VERSION "created by canmatrix"

NS_ :

BS_:

BU_: User ADM_PC_LL25 ADM_PC_BC25 ADM_PC_BP25 ADM_PC_BI25

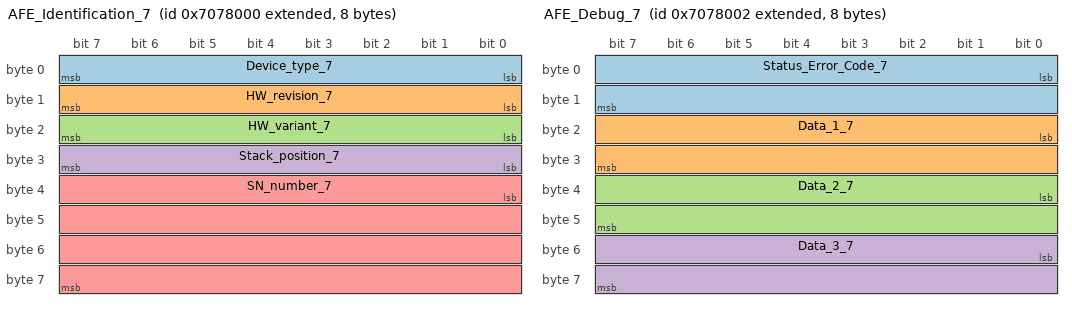
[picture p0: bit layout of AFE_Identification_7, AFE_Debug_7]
BO_ 2265415680 AFE_Identification_7: 8 ADM_PC_BP25
 SG_ Device_type_7 : 0|8@1+ (1,0) [0|255] "" Vector__XXX
 SG_ HW_revision_7 : 8|8@1+ (1,0) [0|255] "" Vector__XXX
 SG_ HW_variant_7 : 16|8@1+ (1,0) [0|255] "" Vector__XXX
 SG_ Stack_position_7 : 24|8@1+ (1,0) [0|255] "" Vector__XXX
 SG_ SN_number_7 : 32|32@1+ (1,0) [0|4294967295] "" Vector__XXX

BO_ 2265415681 AFE_FwInfo_7: 8 ADM_PC_BP25
 SG_ FW_info_mux_7 M : 56|8@1+ (1,0) [0|255] "" Vector__XXX
 SG_ FW_revision_0_7 m0 : 0|8@1+ (1,0) [0|255] "" Vector__XXX
 SG_ FW_revision_1_7 m0 : 8|8@1+ (1,0) [0|255] "" Vector__XXX
 SG_ FW_revision_2_7 m0 : 16|8@1+ (1,0) [0|255] "" Vector__XXX
 SG_ FW_revision_3_7 m0 : 24|8@1+ (1,0) [0|255] "" Vector__XXX
 SG_ FW_revision_4_7 m0 : 32|8@1+ (1,0) [0|255] "" Vector__XXX
 SG_ FW_revision_5_7 m0 : 40|8@1+ (1,0) [0|255] "" Vector__XXX
 SG_ FW_revision_6_7 m0 : 48|8@1+ (1,0) [0|255] "" Vector__XXX
 SG_ FW_revision_7_7 m1 : 0|8@1+ (1,0) [0|255] "" Vector__XXX
 SG_ FW_revision_8_7 m1 : 8|8@1+ (1,0) [0|255] "" Vector__XXX
 SG_ FW_revision_9_7 m1 : 16|8@1+ (1,0) [0|255] "" Vector__XXX
 SG_ FW_revision_10_7 m1 : 24|8@1+ (1,0) [0|255] "" Vector__XXX
 SG_ FW_revision_11_7 m1 : 32|8@1+ (1,0) [0|255] "" Vector__XXX
 SG_ FW_revision_12_7 m1 : 40|8@1+ (1,0) [0|255] "" Vector__XXX
 SG_ FW_revision_13_7 m1 : 48|8@1+ (1,0) [0|255] "" Vector__XXX
 SG_ FW_datecode_0_7 m2 : 0|8@1+ (1,0) [0|255] "" Vector__XXX
 SG_ FW_datecode_1_7 m2 : 8|8@1+ (1,0) [0|255] "" Vector__XXX
 SG_ FW_datecode_2_7 m2 : 16|8@1+ (1,0) [0|255] "" Vector__XXX
 SG_ FW_datecode_3_7 m2 : 24|8@1+ (1,0) [0|255] "" Vector__XXX
 SG_ FW_datecode_4_7 m2 : 32|8@1+ (1,0) [0|255] "" Vector__XXX
 SG_ FW_datecode_5_7 m2 : 40|8@1+ (1,0) [0|255] "" Vector__XXX
 SG_ FW_datecode_6_7 m2 : 48|8@1+ (1,0) [0|255] "" Vector__XXX
 SG_ FW_datecode_7_7 m3 : 0|8@1+ (1,0) [0|255] "" Vector__XXX
 SG_ FW_datecode_8_7 m3 : 8|8@1+ (1,0) [0|255] "" Vector__XXX
 SG_ FW_datecode_9_7 m3 : 16|8@1+ (1,0) [0|255] "" Vector__XXX
 SG_ FW_datecode_10_7 m3 : 24|8@1+ (1,0) [0|255] "" Vector__XXX
 SG_ FW_datecode_11_7 m3 : 32|8@1+ (1,0) [0|255] "" Vector__XXX
 SG_ FW_datecode_12_7 m3 : 40|8@1+ (1,0) [0|255] "" Vector__XXX
 SG_ FW_datecode_13_7 m3 : 48|8@1+ (1,0) [0|255] "" Vector__XXX

BO_ 2265415693 _AFE_Boot_FwInfo_7: 8 ADM_PC_BP25
 SG_ Boot_FW_info_mux_7 M : 56|8@1+ (1,0) [0|255] "" Vector__XXX
 SG_ FW_revision_0_7 m0 : 0|8@1+ (1,0) [0|255] "" Vector__XXX
 SG_ FW_revision_1_7 m0 : 8|8@1+ (1,0) [0|255] "" Vector__XXX
 SG_ FW_revision_2_7 m0 : 16|8@1+ (1,0) [0|255] "" Vector__XXX
 SG_ FW_revision_3_7 m0 : 24|8@1+ (1,0) [0|255] "" Vector__XXX
 SG_ FW_revision_4_7 m0 : 32|8@1+ (1,0) [0|255] "" Vector__XXX
 SG_ FW_revision_5_7 m0 : 40|8@1+ (1,0) [0|255] "" Vector__XXX
 SG_ FW_revision_6_7 m0 : 48|8@1+ (1,0) [0|255] "" Vector__XXX
 SG_ FW_revision_7_7 m1 : 0|8@1+ (1,0) [0|255] "" Vector__XXX
 SG_ FW_revision_8_7 m1 : 8|8@1+ (1,0) [0|255] "" Vector__XXX
 SG_ FW_revision_9_7 m1 : 16|8@1+ (1,0) [0|255] "" Vector__XXX
 SG_ FW_revision_10_7 m1 : 24|8@1+ (1,0) [0|255] "" Vector__XXX
 SG_ FW_revision_11_7 m1 : 32|8@1+ (1,0) [0|255] "" Vector__XXX
 SG_ FW_revision_12_7 m1 : 40|8@1+ (1,0) [0|255] "" Vector__XXX
 SG_ FW_revision_13_7 m1 : 48|8@1+ (1,0) [0|255] "" Vector__XXX
 SG_ FW_datecode_0_7 m2 : 0|8@1+ (1,0) [0|255] "" Vector__XXX
 SG_ FW_datecode_1_7 m2 : 8|8@1+ (1,0) [0|255] "" Vector__XXX
 SG_ FW_datecode_2_7 m2 : 16|8@1+ (1,0) [0|255] "" Vector__XXX
 SG_ FW_datecode_3_7 m2 : 24|8@1+ (1,0) [0|255] "" Vector__XXX
 SG_ FW_datecode_4_7 m2 : 32|8@1+ (1,0) [0|255] "" Vector__XXX
 SG_ FW_datecode_5_7 m2 : 40|8@1+ (1,0) [0|255] "" Vector__XXX
 SG_ FW_datecode_6_7 m2 : 48|8@1+ (1,0) [0|255] "" Vector__XXX
 SG_ FW_datecode_7_7 m3 : 0|8@1+ (1,0) [0|255] "" Vector__XXX
 SG_ FW_datecode_8_7 m3 : 8|8@1+ (1,0) [0|255] "" Vector__XXX
 SG_ FW_datecode_9_7 m3 : 16|8@1+ (1,0) [0|255] "" Vector__XXX
 SG_ FW_datecode_10_7 m3 : 24|8@1+ (1,0) [0|255] "" Vector__XXX
 SG_ FW_datecode_11_7 m3 : 32|8@1+ (1,0) [0|255] "" Vector__XXX
 SG_ FW_datecode_12_7 m3 : 40|8@1+ (1,0) [0|255] "" Vector__XXX
 SG_ FW_datecode_13_7 m3 : 48|8@1+ (1,0) [0|255] "" Vector__XXX

BO_ 2265415682 AFE_Debug_7: 8 ADM_PC_BP25
 SG_ Status_Error_Code_7 : 0|16@1+ (1,0) [0|65535] "" Vector__XXX
 SG_ Data_1_7 : 16|16@1+ (1,0) [0|65535] "" Vector__XXX
 SG_ Data_2_7 : 32|16@1+ (1,0) [0|65535] "" Vector__XXX
 SG_ Data_3_7 : 48|16@1+ (1,0) [0|65535] "" Vector__XXX

BO_ 2265415687 AFE_Status_7: 8 ADM_PC_BP25
 SG_ Running_7 : 0|1@1+ (1,0) [0|1] "" Vector__XXX
 SG_ PWM_7 : 1|1@1+ (1,0) [0|1] "" Vector__XXX
 SG_ Current_dc_loop_mode_7 : 2|1@1+ (1,0) [0|1] "" Vector__XXX
 SG_ Current_ac_loop_mode_7 : 3|1@1+ (1,0) [0|1] "" Vector__XXX
 SG_ Buck_7 : 5|1@1+ (1,0) [0|1] "" Vector__XXX
 SG_ Boost_7 : 6|1@1+ (1,0) [0|1] "" Vector__XXX
 SG_ Precharge_dc_buck_mode_7 : 7|1@1+ (1,0) [0|1] "" Vector__XXX
 SG_ Precharge_dc_boost_mode_7 : 8|1@1+ (1,0) [0|1] "" Vector__XXX
 SG_ Rectifier_3ph_7 : 9|1@1+ (1,0) [0|1] "" Vector__XXX
 SG_ Stack_mode_7 : 10|1@1+ (1,0) [0|1] "" Vector__XXX
 SG_ Master_7 : 11|1@1+ (1,0) [0|1] "" Vector__XXX
 SG_ Slave_7 : 12|1@1+ (1,0) [0|1] "" Vector__XXX
 SG_ Inverter_1ph_7 : 13|1@1+ (1,0) [0|1] "" Vector__XXX
 SG_ Boost_Neutral_7 : 14|1@1+ (1,0) [0|1] "" Vector__XXX
 SG_ Rectifier_1ph_7 : 15|1@1+ (1,0) [0|1] "" Vector__XXX
 SG_ Inverter_3ph_7 : 16|1@1+ (1,0) [0|1] "" Vector__XXX
 SG_ Ready_7 : 17|1@1+ (1,0) [0|1] "" Vector__XXX
 SG_ Inverter_1ph_Sync_7 : 18|1@1+ (1,0) [0|1] "" Vector__XXX
 SG_ Neutral_7 : 19|1@1+ (1,0) [0|1] "" Vector__XXX
 SG_ Rectifier_1ph_Buck_7 : 20|1@1+ (1,0) [0|1] "" Vector__XXX
 SG_ Inverter_1ph_Boost_7 : 21|1@1+ (1,0) [0|1] "" Vector__XXX
 SG_ Rectifier_distributed_7 : 22|1@1+ (1,0) [0|1] "" Vector__XXX
 SG_ MPPT_buck_7 : 23|1@1+ (1,0) [0|1] "" Vector__XXX
 SG_ MPPT_boost_7 : 24|1@1+ (1,0) [0|1] "" Vector__XXX
 SG_ Buck_2p_float_7 : 25|1@1+ (1,0) [0|1] "" Vector__XXX
 SG_ Inverter_1ph_Distributed_7 : 26|1@1+ (1,0) [0|1] "" Vector__XXX

BO_ 2265415686 AFE_Faults_7: 3 ADM_PC_BP25
 SG_ Protection_trip_internal_7 : 0|1@1+ (1,0) [0|1] "" Vector__XXX
 SG_ Protection_trip_external_7 : 1|1@1+ (1,0) [0|1] "" Vector__XXX
 SG_ Phase_U_overcurrent_7 : 2|1@1+ (1,0) [0|1] "" Vector__XXX
 SG_ Phase_U_overvoltage_7 : 3|1@1+ (1,0) [0|1] "" Vector__XXX
 SG_ Phase_U_undervoltage_7 : 4|1@1+ (1,0) [0|1] "" Vector__XXX
 SG_ Phase_V_overvoltage_7 : 5|1@1+ (1,0) [0|1] "" Vector__XXX
 SG_ Phase_V_undervoltage_7 : 6|1@1+ (1,0) [0|1] "" Vector__XXX
 SG_ Phase_V_overcurrent_7 : 7|1@1+ (1,0) [0|1] "" Vector__XXX
 SG_ Phase_W_overvoltage_7 : 8|1@1+ (1,0) [0|1] "" Vector__XXX
 SG_ Phase_W_undervoltage_7 : 9|1@1+ (1,0) [0|1] "" Vector__XXX
 SG_ Phase_W_overcurrent_7 : 10|1@1+ (1,0) [0|1] "" Vector__XXX
 SG_ DC_undervoltage_7 : 11|1@1+ (1,0) [0|1] "" Vector__XXX
 SG_ DC_overvoltage_7 : 12|1@1+ (1,0) [0|1] "" Vector__XXX
 SG_ MOSFET_overtemperature_7 : 13|1@1+ (1,0) [0|1] "" Vector__XXX
 SG_ Inductor_overtemperature_7 : 14|1@1+ (1,0) [0|1] "" Vector__XXX
 SG_ Keep_Alive_not_served_7 : 15|1@1+ (1,0) [0|1] "" Vector__XXX
 SG_ PLL_not_locked_7 : 16|1@1+ (1,0) [0|1] "" Vector__XXX
 SG_ NFO_7 : 20|1@1+ (1,0) [0|1] "" Vector__XXX
 SG_ Measurement_system_failure_7 : 21|1@1+ (1,0) [0|1] "" Vector__XXX
 SG_ EEPROM_failure_7 : 22|1@1+ (1,0) [0|1] "" Vector__XXX
 SG_ System_7 : 23|1@1+ (1,0) [0|1] "" Vector__XXX

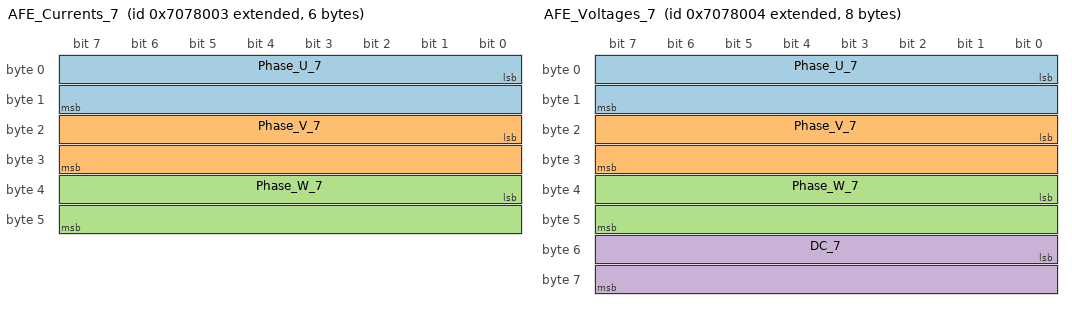
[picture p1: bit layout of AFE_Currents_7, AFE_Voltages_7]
BO_ 2265415683 AFE_Currents_7: 6 ADM_PC_BP25
 SG_ Phase_U_7 : 0|16@1- (0.01,0) [-327.68|327.67] "A" Vector__XXX
 SG_ Phase_V_7 : 16|16@1- (0.01,0) [-327.68|327.67] "A" Vector__XXX
 SG_ Phase_W_7 : 32|16@1- (0.01,0) [-327.68|327.67] "A" Vector__XXX

BO_ 2265415696 AFE_DC_Bus_current_7: 2 ADM_PC_BP25
 SG_ Bus_current_7 : 0|16@1- (0.01,0) [-327.68|327.67] "A" Vector__XXX

BO_ 2265415694 _AFE_Broadcast_7: 8 ADM_PC_BP25
 SG_ Diagnostics_Index_7 M : 56|8@1+ (1,0) [0|255] "" Vector__XXX
 SG_ Phase_U_7 m1 : 8|16@1- (0.01,0) [-327.68|327.67] "A" ADM_PC_BP25
 SG_ Phase_V_7 m1 : 24|16@1- (0.01,0) [-327.68|327.67] "A" ADM_PC_BP25
 SG_ Phase_W_7 m1 : 40|16@1- (0.01,0) [-327.68|327.67] "A" ADM_PC_BP25
 SG_ Stack_position_7 : 0|5@1+ (1,0) [0|31] "" ADM_PC_BP25
 SG_ Group_ID_7 : 5|3@1+ (1,0) [0|7] "" ADM_PC_BP25

BO_ 2265415684 AFE_Voltages_7: 8 ADM_PC_BP25
 SG_ Phase_U_7 : 0|16@1- (0.1,0) [-3276.8|3276.7] "V" Vector__XXX
 SG_ Phase_V_7 : 16|16@1- (0.1,0) [-3276.8|3276.7] "V" Vector__XXX
 SG_ Phase_W_7 : 32|16@1- (0.1,0) [-3276.8|3276.7] "V" Vector__XXX
 SG_ DC_7 : 48|16@1- (0.1,0) [-3276.8|3276.7] "V" Vector__XXX

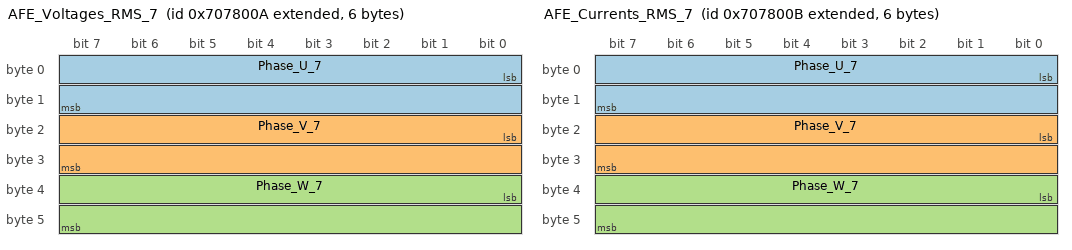
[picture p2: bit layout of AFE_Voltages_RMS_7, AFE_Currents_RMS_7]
BO_ 2265415690 AFE_Voltages_RMS_7: 6 ADM_PC_BP25
 SG_ Phase_U_7 : 0|16@1+ (0.1,0) [0|6553.5] "V" Vector__XXX
 SG_ Phase_V_7 : 16|16@1+ (0.1,0) [0|6553.5] "V" Vector__XXX
 SG_ Phase_W_7 : 32|16@1+ (0.1,0) [0|6553.5] "V" Vector__XXX

BO_ 2265415691 AFE_Currents_RMS_7: 6 ADM_PC_BP25
 SG_ Phase_U_7 : 0|16@1+ (0.01,0) [0.00|655.35] "A" Vector__XXX
 SG_ Phase_V_7 : 16|16@1+ (0.01,0) [0.00|655.35] "A" Vector__XXX
 SG_ Phase_W_7 : 32|16@1+ (0.01,0) [0.00|655.35] "A" Vector__XXX

BO_ 2265415692 AFE_Mains_7: 4 ADM_PC_BP25
 SG_ Frequency_7 : 0|16@1+ (0.01,0) [0.00|655.35] "Hz" Vector__XXX
 SG_ Phase_7 : 16|16@1- (0.1,0) [-3276.8|3276.7] "Deg." Vector__XXX

BO_ 2265415685 AFE_Temperatures_7: 4 ADM_PC_BP25
 SG_ Temp_Bridge_7 : 0|16@1- (0.01,0) [-327.68|327.67] "°C" Vector__XXX
 SG_ Temp_Inductors_7 : 16|16@1- (0.01,0) [-327.68|327.67] "°C" Vector__XXX

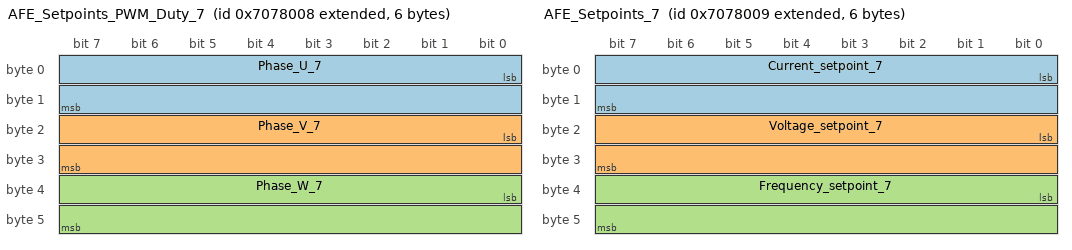
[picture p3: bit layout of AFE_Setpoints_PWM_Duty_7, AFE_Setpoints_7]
BO_ 2265415688 AFE_Setpoints_PWM_Duty_7: 6 ADM_PC_BP25
 SG_ Phase_U_7 : 0|16@1+ (0.001525902,0) [0E-009|99.999987570] "%" Vector__XXX
 SG_ Phase_V_7 : 16|16@1+ (0.001525902,0) [0E-009|99.999987570] "%" Vector__XXX
 SG_ Phase_W_7 : 32|16@1+ (0.001525902,0) [0E-009|99.999987570] "%" Vector__XXX

BO_ 2265415689 AFE_Setpoints_7: 6 ADM_PC_BP25
 SG_ Current_setpoint_7 : 0|16@1- (0.01,0) [-327.68|327.67] "A" Vector__XXX
 SG_ Voltage_setpoint_7 : 16|16@1+ (0.1,0) [0|6553.5] "V" Vector__XXX
 SG_ Frequency_setpoint_7 : 32|16@1+ (0.01,0) [0.00|655.35] "Hz" Vector__XXX

BO_ 2265383008 AFE_Keep_Alive_7: 1 User
 SG_ Keep_Alive_Enable_7 : 0|1@1+ (1,0) [0|1] "" ADM_PC_BP25

BO_ 2265382976 AFE_Mode_Control_7: 8 User
 SG_ Converter_ON_7 : 0|1@1+ (1,0) [0|1] "" ADM_PC_BP25
 SG_ PWM_ON_7 : 1|1@1+ (1,0) [0|1] "" ADM_PC_BP25
 SG_ DC_Current_feedback_ON_7 : 2|1@1+ (1,0) [0|1] "" ADM_PC_BP25
 SG_ AC_Current_feedback_ON_7 : 3|1@1+ (1,0) [0|1] "" ADM_PC_BP25
 SG_ Buck_ON_7 : 5|1@1+ (1,0) [0|1] "" ADM_PC_BP25
 SG_ Boost_ON_7 : 6|1@1+ (1,0) [0|1] "" ADM_PC_BP25
 SG_ Rectifier_3ph_ON_7 : 9|1@1+ (1,0) [0|1] "" ADM_PC_BP25
 SG_ Inverter_1ph_ON_7 : 10|1@1+ (1,0) [0|1] "" ADM_PC_BP25
 SG_ Rectifier_1ph_ON_7 : 11|1@1+ (1,0) [0|1] "" ADM_PC_BP25
 SG_ Boost_Neutral_ON_7 : 12|1@1+ (1,0) [0|1] "" ADM_PC_BP25
 SG_ Inverter_3ph_ON_7 : 13|1@1+ (1,0) [0|1] "" ADM_PC_BP25
 SG_ Inverter_1ph_Sync_ON_7 : 14|1@1+ (1,0) [0|1] "" ADM_PC_BP25
 SG_ Neutral_ON_7 : 15|1@1+ (1,0) [0|1] "" ADM_PC_BP25
 SG_ Rectifier_1ph_Buck_ON_7 : 16|1@1+ (1,0) [0|1] "" ADM_PC_BP25
 SG_ Inverter_1ph_Boost_ON_7 : 17|1@1+ (1,0) [0|1] "" ADM_PC_BP25
 SG_ Rectifier_Distributed_ON_7 : 18|1@1+ (1,0) [0|1] "" ADM_PC_BP25
 SG_ MPPT_buck_ON_7 : 19|1@1+ (1,0) [0|1] "" ADM_PC_BP25
 SG_ MPPT_boost_ON_7 : 20|1@1+ (1,0) [0|1] "" ADM_PC_BP25
 SG_ Buck_2p_float_ON_7 : 21|1@1+ (1,0) [0|1] "" ADM_PC_BP25
 SG_ Inverter_1ph_Distributed_ON_7 : 22|1@1+ (1,0) [0|1] "" ADM_PC_BP25

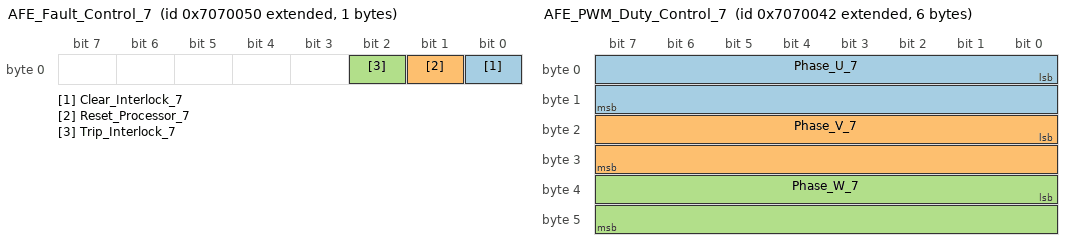
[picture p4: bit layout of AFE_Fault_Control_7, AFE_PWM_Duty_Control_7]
BO_ 2265382992 AFE_Fault_Control_7: 1 User
 SG_ Clear_Interlock_7 : 0|1@1+ (1,0) [0|1] "" ADM_PC_BP25
 SG_ Reset_Processor_7 : 1|1@1+ (1,0) [0|1] "" ADM_PC_BP25
 SG_ Trip_Interlock_7 : 2|1@1+ (1,0) [0|1] "" ADM_PC_BP25

BO_ 2265382977 AFE_Reactive_Current_Setpoint_Co: 2 User
 SG_ Reactive_current_setpoint_7 : 0|16@1- (0.01,0) [-150|150] "A" ADM_PC_BP25

BO_ 2265382978 AFE_PWM_Duty_Control_7: 6 User
 SG_ Phase_U_7 : 0|16@1+ (0.001525902,0) [0E-009|99.999987570] "%" ADM_PC_BP25
 SG_ Phase_V_7 : 16|16@1+ (0.001525902,0) [0E-009|99.999987570] "%" ADM_PC_BP25
 SG_ Phase_W_7 : 32|16@1+ (0.001525902,0) [0E-009|99.999987570] "%" ADM_PC_BP25

BO_ 2265382979 AFE_Current_Setpoint_Control_7: 2 User
 SG_ Current_setpoint_7 : 0|16@1- (0.01,0) [-150|150] "A" ADM_PC_BP25

BO_ 2265382980 AFE_Voltage_Setpoint_Control_7: 2 User
 SG_ Voltage_setpoint_7 : 0|16@1+ (0.1,0) [0|1500] "V" ADM_PC_BP25

BO_ 2265382984 AFE_Frequency_Setpoint_Control_7: 2 User
 SG_ Frequency_setpoint_7 : 0|16@1+ (0.01,0) [40|70] "Hz" ADM_PC_BP25

BO_ 2265382985 AFE_Phase_Setpoint_Control_7: 2 User
 SG_ Phase_setpoint_7 : 0|16@1+ (1,0) [0|360] "deg" ADM_PC_BP25

BO_ 2265383024 AFE_Rectifier_Setpoint_Control_7: 8 User
 SG_ Voltage_setpoint_2_7 : 0|16@1+ (0.1,0) [0|1500] "V" ADM_PC_BP25
 SG_ Current_setpoint_2_7 : 16|16@1- (0.01,0) [-150|150] "A" ADM_PC_BP25

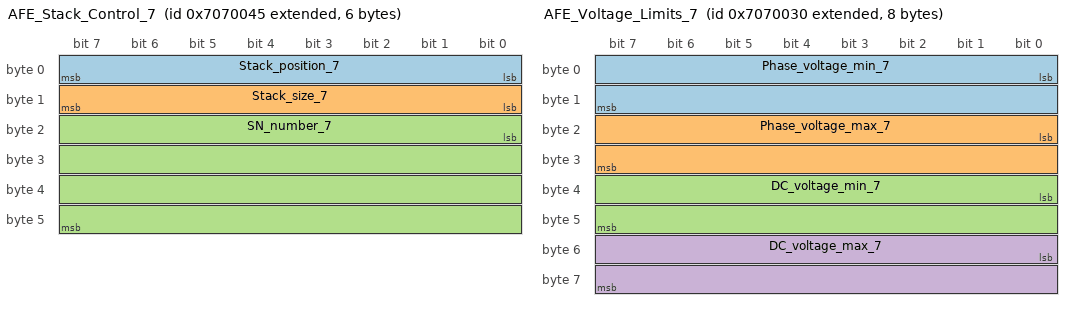
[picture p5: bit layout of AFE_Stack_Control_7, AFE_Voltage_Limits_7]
BO_ 2265382981 AFE_Stack_Control_7: 6 User
 SG_ Stack_position_7 : 0|8@1+ (1,0) [0|255] "" ADM_PC_BP25
 SG_ Stack_size_7 : 8|8@1+ (1,0) [0|255] "" ADM_PC_BP25
 SG_ SN_number_7 : 16|32@1+ (1,0) [0|4294967295] "" ADM_PC_BP25

BO_ 2265382960 AFE_Voltage_Limits_7: 8 User
 SG_ Phase_voltage_min_7 : 0|16@1- (0.1,0) [0|3276.7] "V" ADM_PC_BP25
 SG_ Phase_voltage_max_7 : 16|16@1- (0.1,0) [-3276.8|850] "V" ADM_PC_BP25
 SG_ DC_voltage_min_7 : 32|16@1- (0.1,0) [0|3276.7] "V" ADM_PC_BP25
 SG_ DC_voltage_max_7 : 48|16@1- (0.1,0) [-3276.8|850] "V" ADM_PC_BP25

BO_ 2265382961 AFE_Current_Limits_7: 4 User
 SG_ Phase_current_min_7 : 0|16@1- (0.01,0) [-60|60] "A" ADM_PC_BP25
 SG_ Phase_current_max_7 : 16|16@1- (0.01,0) [-60|60] "A" ADM_PC_BP25

BO_ 2265382988 AFE_Group_Control_7: 1 User
 SG_ Group_ID_7 : 0|8@1+ (1,0) [0|255] "" ADM_PC_BP25

BO_ 2265415695 AFE_Group_Info_7: 1 ADM_PC_BP25
 SG_ Group_ID_7 : 0|8@1+ (1,0) [0|255] "" Vector__XXX

BO_ 2265383009 AFE_System_Flags_Control_7: 8 User
 SG_ Factory_mode_7 : 0|1@1+ (1,0) [0|1] "" ADM_PC_BP25
 SG_ Silent_CAN_mode_7 : 1|1@1+ (1,0) [0|1] "" ADM_PC_BP25

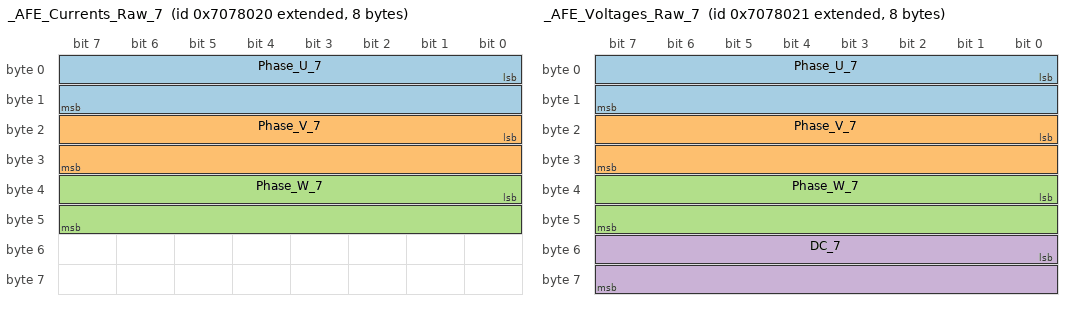
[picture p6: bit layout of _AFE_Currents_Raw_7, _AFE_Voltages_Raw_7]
BO_ 2265415712 _AFE_Currents_Raw_7: 8 ADM_PC_BP25
 SG_ Phase_U_7 : 0|16@1- (1,0) [-32768|32767] "" Vector__XXX
 SG_ Phase_V_7 : 16|16@1- (1,0) [-32768|32767] "" Vector__XXX
 SG_ Phase_W_7 : 32|16@1- (1,0) [-32768|32767] "" Vector__XXX

BO_ 2265415713 _AFE_Voltages_Raw_7: 8 ADM_PC_BP25
 SG_ Phase_U_7 : 0|16@1- (1,0) [-32768|32767] "" Vector__XXX
 SG_ Phase_V_7 : 16|16@1- (1,0) [-32768|32767] "" Vector__XXX
 SG_ Phase_W_7 : 32|16@1- (1,0) [-32768|32767] "" Vector__XXX
 SG_ DC_7 : 48|16@1- (1,0) [-32768|32767] "" Vector__XXX

BO_ 2265382986 _AFE_ADC_Calibration_Mode_7: 1 User
 SG_ Calibration_Index_7 M : 2|5@1+ (1,0) [0|31] "" Vector__XXX
 SG_ Current_U_7 m1 : 0|2@1+ (1,0) [0|3] "" ADM_PC_BP25
 SG_ Current_V_7 m2 : 0|2@1+ (1,0) [0|3] "" ADM_PC_BP25
 SG_ Current_W_7 m3 : 0|2@1+ (1,0) [0|3] "" ADM_PC_BP25
 SG_ Voltage_U_7 m4 : 0|2@1+ (1,0) [0|3] "" ADM_PC_BP25
 SG_ Voltage_V_7 m5 : 0|2@1+ (1,0) [0|3] "" ADM_PC_BP25
 SG_ Voltage_W_7 m6 : 0|2@1+ (1,0) [0|3] "" ADM_PC_BP25
 SG_ Voltage_DC_7 m7 : 0|2@1+ (1,0) [0|3] "" ADM_PC_BP25
 SG_ start_7 : 7|1@1+ (1,0) [0|1] "" ADM_PC_BP25

BO_ 2265382987 _AFE_ADC_Calibration_Setpoint_7: 3 User
 SG_ Calibration_Index_7 M : 16|5@1+ (1,0) [0|31] "" Vector__XXX
 SG_ Current_U_7 m1 : 0|16@1- (0.01,0) [-100|100] "A" ADM_PC_BP25
 SG_ Current_V_7 m2 : 0|16@1- (0.01,0) [-100|100] "A" ADM_PC_BP25
 SG_ Current_W_7 m3 : 0|16@1- (0.01,0) [-100|100] "A" ADM_PC_BP25
 SG_ Voltage_U_7 m4 : 0|16@1+ (0.1,0) [0|1500] "V" ADM_PC_BP25
 SG_ Voltage_V_7 m5 : 0|16@1+ (0.1,0) [0|1500] "V" ADM_PC_BP25
 SG_ Voltage_W_7 m6 : 0|16@1+ (0.1,0) [0|1500] "V" ADM_PC_BP25
 SG_ Voltage_DC_7 m7 : 0|16@1+ (0.1,0) [0|1500] "V" ADM_PC_BP25
 SG_ point_7 : 21|3@1+ (1,0) [0|7] "" ADM_PC_BP25

BO_ 2265382982 _AFE_Calibration_Offset_Update_7: 6 User
 SG_ Calibration_Index_7 M : 16|16@1+ (1,0) [0|65535] "" Vector__XXX
 SG_ Current_U_7 m0 : 0|16@1- (1,0) [-32768|32767] "ADC Counts" ADM_PC_BP25
 SG_ Current_V_7 m1 : 0|16@1- (1,0) [-32768|32767] "ADC Counts" ADM_PC_BP25
 SG_ Current_W_7 m2 : 0|16@1- (1,0) [-32768|32767] "ADC Counts" ADM_PC_BP25
 SG_ Voltage_U_7 m3 : 0|16@1- (1,0) [-32768|32767] "ADC Counts" ADM_PC_BP25
 SG_ Voltage_V_7 m4 : 0|16@1- (1,0) [-32768|32767] "ADC Counts" ADM_PC_BP25
 SG_ Voltage_W_7 m5 : 0|16@1- (1,0) [-32768|32767] "ADC Counts" ADM_PC_BP25
 SG_ Voltage_DC_7 m6 : 0|16@1- (1,0) [-32768|32767] "ADC Counts" ADM_PC_BP25
 SG_ CRC_7 : 32|16@1+ (1,0) [0|65535] "-" ADM_PC_BP25

BO_ 2265382983 _AFE_Calibration_Scale_Update_7: 6 User
 SG_ Calibration_Index_7 M : 16|16@1+ (1,0) [0|65535] "" Vector__XXX
 SG_ Current_U_7 m0 : 0|16@1- (0.0000152587890625,0) [-0.5000000000000000|0.4999847412109375] "scale = 1.0 + value" ADM_PC_BP25
 SG_ Current_V_7 m1 : 0|16@1- (0.0000152587890625,0) [-0.5000000000000000|0.4999847412109375] "scale = 1.0 + value" ADM_PC_BP25
 SG_ Current_W_7 m2 : 0|16@1- (0.0000152587890625,0) [-0.5000000000000000|0.4999847412109375] "scale = 1.0 + value" ADM_PC_BP25
 SG_ Voltage_U_7 m3 : 0|16@1- (0.0000152587890625,0) [-0.5000000000000000|0.4999847412109375] "scale = 1.0 + value" ADM_PC_BP25
 SG_ Voltage_V_7 m4 : 0|16@1- (0.0000152587890625,0) [-0.5000000000000000|0.4999847412109375] "scale = 1.0 + value" ADM_PC_BP25
 SG_ Voltage_W_7 m5 : 0|16@1- (0.0000152587890625,0) [-0.5000000000000000|0.4999847412109375] "scale = 1.0 + value" ADM_PC_BP25
 SG_ Voltage_DC_7 m6 : 0|16@1- (0.0000152587890625,0) [-0.5000000000000000|0.4999847412109375] "scale = 1.0 + value" ADM_PC_BP25
 SG_ CRC_7 : 32|16@1+ (1,0) [0|65535] "-" ADM_PC_BP25

BO_ 2265415761 _AFE_Calibration_Adc_Scale_7: 6 ADM_PC_BP25
 SG_ Adc_Index_7 M : 32|16@1+ (1,0) [0|65535] "" Vector__XXX
 SG_ Current_U_7 m0 : 0|32@1+ (1,0) [0|4294967295] "1 / adc_bins" User
 SG_ Current_V_7 m1 : 0|32@1+ (1,0) [0|4294967295] "1 / adc_bins" User
 SG_ Current_W_7 m2 : 0|32@1+ (1,0) [0|4294967295] "1 / adc_bins" User
 SG_ Voltage_U_7 m3 : 0|32@1+ (1,0) [0|4294967295] "1 / adc_bins" User
 SG_ Voltage_V_7 m4 : 0|32@1+ (1,0) [0|4294967295] "1 / adc_bins" User
 SG_ Voltage_W_7 m5 : 0|32@1+ (1,0) [0|4294967295] "1 / adc_bins" User
 SG_ Voltage_DC_7 m6 : 0|32@1+ (1,0) [0|4294967295] "1 / adc_bins" User

BO_ 2265415762 _AFE_Calibration_Adc_Fs_7: 6 ADM_PC_BP25
 SG_ Adc_Index_7 M : 32|16@1+ (1,0) [0|65535] "" Vector__XXX
 SG_ Current_U_7 m0 : 0|32@1+ (1,0) [0|4294967295] "Fullscale" User
 SG_ Current_V_7 m1 : 0|32@1+ (1,0) [0|4294967295] "Fullscale" User
 SG_ Current_W_7 m2 : 0|32@1+ (1,0) [0|4294967295] "Fullscale" User
 SG_ Voltage_U_7 m3 : 0|32@1+ (1,0) [0|4294967295] "Fullscale" User
 SG_ Voltage_V_7 m4 : 0|32@1+ (1,0) [0|4294967295] "Fullscale" User
 SG_ Voltage_W_7 m5 : 0|32@1+ (1,0) [0|4294967295] "Fullscale" User
 SG_ Voltage_DC_7 m6 : 0|32@1+ (1,0) [0|4294967295] "Fullscale" User

BO_ 2265415763 _AFE_Calibration_Adc_Offset_7: 4 ADM_PC_BP25
 SG_ Adc_Index_7 M : 16|16@1+ (1,0) [0|65535] "" Vector__XXX
 SG_ Current_U_7 m0 : 0|16@1- (1,0) [-32768|32767] "-" User
 SG_ Current_V_7 m1 : 0|16@1- (1,0) [-32768|32767] "-" User
 SG_ Current_W_7 m2 : 0|16@1- (1,0) [-32768|32767] "-" User
 SG_ Voltage_U_7 m3 : 0|16@1- (1,0) [-32768|32767] "-" User
 SG_ Voltage_V_7 m4 : 0|16@1- (1,0) [-32768|32767] "-" User
 SG_ Voltage_W_7 m5 : 0|16@1- (1,0) [-32768|32767] "-" User
 SG_ Voltage_DC_7 m6 : 0|16@1- (1,0) [-32768|32767] "-" User

BO_ 2265415764 _AFE_Calibration_Adc_Gain_7: 4 ADM_PC_BP25
 SG_ Adc_Index_7 M : 16|16@1+ (1,0) [0|65535] "" Vector__XXX
 SG_ Current_U_7 m0 : 0|16@1- (1,0) [-32768|32767] "-" User
 SG_ Current_V_7 m1 : 0|16@1- (1,0) [-32768|32767] "-" User
 SG_ Current_W_7 m2 : 0|16@1- (1,0) [-32768|32767] "-" User
 SG_ Voltage_U_7 m3 : 0|16@1- (1,0) [-32768|32767] "-" User
 SG_ Voltage_V_7 m4 : 0|16@1- (1,0) [-32768|32767] "-" User
 SG_ Voltage_W_7 m5 : 0|16@1- (1,0) [-32768|32767] "-" User
 SG_ Voltage_DC_7 m6 : 0|16@1- (1,0) [-32768|32767] "-" User

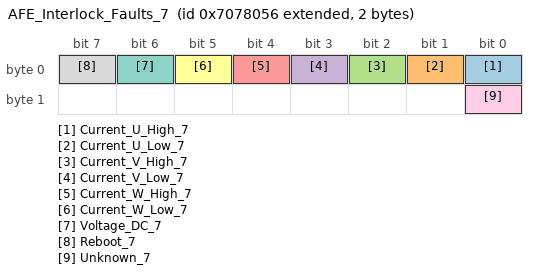
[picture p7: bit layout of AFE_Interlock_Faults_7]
BO_ 2265415766 AFE_Interlock_Faults_7: 2 ADM_PC_BP25
 SG_ Current_U_High_7 : 0|1@1+ (1,0) [0|1] "" Vector__XXX
 SG_ Current_U_Low_7 : 1|1@1+ (1,0) [0|1] "" Vector__XXX
 SG_ Current_V_High_7 : 2|1@1+ (1,0) [0|1] "" Vector__XXX
 SG_ Current_V_Low_7 : 3|1@1+ (1,0) [0|1] "" Vector__XXX
 SG_ Current_W_High_7 : 4|1@1+ (1,0) [0|1] "" Vector__XXX
 SG_ Current_W_Low_7 : 5|1@1+ (1,0) [0|1] "" Vector__XXX
 SG_ Voltage_DC_7 : 6|1@1+ (1,0) [0|1] "" Vector__XXX
 SG_ Reboot_7 : 7|1@1+ (1,0) [0|1] "" Vector__XXX
 SG_ Unknown_7 : 8|1@1+ (1,0) [0|1] "" Vector__XXX

BO_TX_BU_ 2265382976 : User,ADM_PC_LL25,ADM_PC_BC25,ADM_PC_BI25;
BO_TX_BU_ 2265382979 : User,ADM_PC_LL25,ADM_PC_BC25,ADM_PC_BI25;
BO_TX_BU_ 2265382980 : User,ADM_PC_LL25,ADM_PC_BC25,ADM_PC_BI25;
CM_ BO_ 2265415680  "Identification of the device";
CM_ BO_ 2265415681  "Git revision of the DSP firmware";
CM_ BO_ 2265415693  "Git revision of the bootloader firmware.";
CM_ BO_ 2265415682  "Values for debugging of HW/SW problems";
CM_ BO_ 2265415687  "Status bitfield";
CM_ BO_ 2265415686  "Fault bitfield";
CM_ BO_ 2265415683  "Current of phases U, V, W";
CM_ BO_ 2265415696  "Current of of the DC Bus";
CM_ BO_ 2265415694  "All AFEs will listen to this message";
CM_ BO_ 2265415691  "RMS Current of phases U, V, W";
CM_ BO_ 2265415692  "Three-Phase mains health (frequency, phase...)";
CM_ BO_ 2265415685  "Readouts of the module temperature sensors";
CM_ BO_ 2265415688  "Setpoints";
CM_ BO_ 2265415689  "Setpoints";
CM_ BO_ 2265383008  "Keep alive ping message. ";
CM_ BO_ 2265382976  "Operation Mode control: sets the converter operation mode";
CM_ BO_ 2265382992  "Fault Control: actions to clear faults and reset the system";
CM_ BO_ 2265382977  "Reactive power setpoint control.";
CM_ BO_ 2265382978  "PWM duty cycle control";
CM_ BO_ 2265382979  "Current setpoint control";
CM_ BO_ 2265382980  "Voltage setpoint control";
CM_ BO_ 2265382984  "Frequency setpoint control";
CM_ BO_ 2265382985  "Phase setpoint control";
CM_ BO_ 2265383024  "Additional voltage and current setpoints in single-phase rectifier and inverter control modes.";
CM_ BO_ 2265382981  "PFC stack control";
CM_ BO_ 2265382960  "Set the input and output voltage limits (minimum and maximum)";
CM_ BO_ 2265382961  "Set the output current limits (mminimum and maximum)";
CM_ BO_ 2265382988  "Set the Group ID of the device";
CM_ BO_ 2265415695  "Contains the Group ID of the device";
CM_ BO_ 2265383009  "Control the system flags";
CM_ BO_ 2265415712  "Current of phases A and B";
CM_ BO_ 2265415713  "Current of phases A and B";
CM_ BO_ 2265382986  "Automatic ADC calibration.";
CM_ BO_ 2265382987  "Setpoint for automatic ADC calibration.";
CM_ BO_ 2265382982  "Update of the calibration table for offsets.";
CM_ BO_ 2265382983  "Update of the calibration table for scales.";
CM_ BO_ 2265415761  "
                Adc scale (resolution) value of readouts.
            ";
CM_ BO_ 2265415762  "
                Adc fullscale value of readouts.
            ";
CM_ BO_ 2265415763  "
                Readout of ADC calibration data (offset) from EEPROM.
            ";
CM_ BO_ 2265415764  "
                Readout of ADC calibration data (gain) from EEPROM.
            ";
CM_ BO_ 2265415766  "Fault bitfield";

CM_ SG_ 2265415680 Device_type_7 "The device identification field, uniquely identifies the sender in the network";
CM_ SG_ 2265415680 HW_revision_7 "The hardware revision number";
CM_ SG_ 2265415680 HW_variant_7 "The DSP firmware revision number";
CM_ SG_ 2265415680 Stack_position_7 "Position of the module within the stack";
CM_ SG_ 2265415680 SN_number_7 "Unique module serial number";
CM_ SG_ 2265415681 FW_revision_0_7 "Character 0";
CM_ SG_ 2265415681 FW_revision_1_7 "Character 1";
CM_ SG_ 2265415681 FW_revision_2_7 "Character 2";
CM_ SG_ 2265415681 FW_revision_3_7 "Character 3";
CM_ SG_ 2265415681 FW_revision_4_7 "Character 3";
CM_ SG_ 2265415681 FW_revision_5_7 "Character 3";
CM_ SG_ 2265415681 FW_revision_6_7 "Character 3";
CM_ SG_ 2265415681 FW_revision_7_7 "Character 7";
CM_ SG_ 2265415681 FW_revision_8_7 "Character 8";
CM_ SG_ 2265415681 FW_revision_9_7 "Character 9";
CM_ SG_ 2265415681 FW_revision_10_7 "Character 10";
CM_ SG_ 2265415681 FW_revision_11_7 "Character 11";
CM_ SG_ 2265415681 FW_revision_12_7 "Character 12";
CM_ SG_ 2265415681 FW_revision_13_7 "Character 13";
CM_ SG_ 2265415681 FW_datecode_0_7 "Character 0";
CM_ SG_ 2265415681 FW_datecode_1_7 "Character 1";
CM_ SG_ 2265415681 FW_datecode_2_7 "Character 2";
CM_ SG_ 2265415681 FW_datecode_3_7 "Character 3";
CM_ SG_ 2265415681 FW_datecode_4_7 "Character 3";
CM_ SG_ 2265415681 FW_datecode_5_7 "Character 3";
CM_ SG_ 2265415681 FW_datecode_6_7 "Character 3";
CM_ SG_ 2265415681 FW_datecode_7_7 "Character 7";
CM_ SG_ 2265415681 FW_datecode_8_7 "Character 8";
CM_ SG_ 2265415681 FW_datecode_9_7 "Character 9";
CM_ SG_ 2265415681 FW_datecode_10_7 "Character 10";
CM_ SG_ 2265415681 FW_datecode_11_7 "Character 11";
CM_ SG_ 2265415681 FW_datecode_12_7 "Character 12";
CM_ SG_ 2265415681 FW_datecode_13_7 "Character 13";
CM_ SG_ 2265415693 FW_revision_0_7 "Character 0";
CM_ SG_ 2265415693 FW_revision_1_7 "Character 1";
CM_ SG_ 2265415693 FW_revision_2_7 "Character 2";
CM_ SG_ 2265415693 FW_revision_3_7 "Character 3";
CM_ SG_ 2265415693 FW_revision_4_7 "Character 3";
CM_ SG_ 2265415693 FW_revision_5_7 "Character 3";
CM_ SG_ 2265415693 FW_revision_6_7 "Character 3";
CM_ SG_ 2265415693 FW_revision_7_7 "Character 7";
CM_ SG_ 2265415693 FW_revision_8_7 "Character 8";
CM_ SG_ 2265415693 FW_revision_9_7 "Character 9";
CM_ SG_ 2265415693 FW_revision_10_7 "Character 10";
CM_ SG_ 2265415693 FW_revision_11_7 "Character 11";
CM_ SG_ 2265415693 FW_revision_12_7 "Character 12";
CM_ SG_ 2265415693 FW_revision_13_7 "Character 13";
CM_ SG_ 2265415693 FW_datecode_0_7 "Character 0";
CM_ SG_ 2265415693 FW_datecode_1_7 "Character 1";
CM_ SG_ 2265415693 FW_datecode_2_7 "Character 2";
CM_ SG_ 2265415693 FW_datecode_3_7 "Character 3";
CM_ SG_ 2265415693 FW_datecode_4_7 "Character 3";
CM_ SG_ 2265415693 FW_datecode_5_7 "Character 3";
CM_ SG_ 2265415693 FW_datecode_6_7 "Character 3";
CM_ SG_ 2265415693 FW_datecode_7_7 "Character 7";
CM_ SG_ 2265415693 FW_datecode_8_7 "Character 8";
CM_ SG_ 2265415693 FW_datecode_9_7 "Character 9";
CM_ SG_ 2265415693 FW_datecode_10_7 "Character 10";
CM_ SG_ 2265415693 FW_datecode_11_7 "Character 11";
CM_ SG_ 2265415693 FW_datecode_12_7 "Character 12";
CM_ SG_ 2265415693 FW_datecode_13_7 "Character 13";
CM_ SG_ 2265415682 Status_Error_Code_7 "Main status / error code as defined in errno/errno.h";
CM_ SG_ 2265415682 Data_1_7 "Additional information for the error/status";
CM_ SG_ 2265415682 Data_2_7 "Additional information for the error/status";
CM_ SG_ 2265415682 Data_3_7 "Additional information for the error/status";
CM_ SG_ 2265415687 Running_7 "Indicates if converter is running.";
CM_ SG_ 2265415687 PWM_7 "Indicates if converter is in PWM control mode.";
CM_ SG_ 2265415687 Current_dc_loop_mode_7 "Indicates if the current DC loop is enabled.";
CM_ SG_ 2265415687 Current_ac_loop_mode_7 "Indicates if the current AC loop is enabled.";
CM_ SG_ 2265415687 Buck_7 "Indicates if converter is in buck control mode.";
CM_ SG_ 2265415687 Boost_7 "Indicates if converter is in boost control mode.";
CM_ SG_ 2265415687 Precharge_dc_buck_mode_7 "Indicates if the precharge DC mode is enabled - buck direction.";
CM_ SG_ 2265415687 Precharge_dc_boost_mode_7 "Indicates if the precharge DC mode is enabled - boost direction.";
CM_ SG_ 2265415687 Rectifier_3ph_7 "Indicates if converter is in three-phase rectifier control mode.";
CM_ SG_ 2265415687 Stack_mode_7 "Indicates if converter is operating in stack mode.";
CM_ SG_ 2265415687 Master_7 "Indicates if converter is master in the stack.";
CM_ SG_ 2265415687 Slave_7 "Indicates if converter is slave in the stack.";
CM_ SG_ 2265415687 Inverter_1ph_7 "Indicates if converter is in single-phase inverter control mode.";
CM_ SG_ 2265415687 Boost_Neutral_7 "Indicates if converter is in boost control mode with neutral generation.";
CM_ SG_ 2265415687 Rectifier_1ph_7 "Indicates if converter is in single-phase rectifier control mode.";
CM_ SG_ 2265415687 Inverter_3ph_7 "Indicates if converter is in three-phase inverter control mode.";
CM_ SG_ 2265415687 Ready_7 "Indicates if converter is ready for operation.";
CM_ SG_ 2265415687 Inverter_1ph_Sync_7 "Single-phase inverter control mode with phase synchronization.";
CM_ SG_ 2265415687 Neutral_7 "Open-loop neutral generation.";
CM_ SG_ 2265415687 Rectifier_1ph_Buck_7 "Single-phase rectifier with buck on one leg.";
CM_ SG_ 2265415687 Inverter_1ph_Boost_7 "Single-phase inverter with boost on one leg.";
CM_ SG_ 2265415687 Rectifier_distributed_7 "Not available at the moment";
CM_ SG_ 2265415687 MPPT_buck_7 "Not available at the moment";
CM_ SG_ 2265415687 MPPT_boost_7 "Not available at the moment";
CM_ SG_ 2265415687 Buck_2p_float_7 "Buck in phases L1 and L2. Phase L3 is left floating (high impedance)";
CM_ SG_ 2265415687 Inverter_1ph_Distributed_7 "Single-phase inverter mode  distributed";
CM_ SG_ 2265415686 Protection_trip_internal_7 "This flagg is asserted if the interlock is open due to an internal fault condition (self-protection)";
CM_ SG_ 2265415686 Protection_trip_external_7 "This flag is asserted if the interlock is open due to an external condition received in the module.";
CM_ SG_ 2265415686 Phase_U_overcurrent_7 "Indicates an overcurrent event on Phase U. The overcurrent event is triggered when the measured phase current is over the programmed current limit.";
CM_ SG_ 2265415686 Phase_U_overvoltage_7 "Indicates an overvoltage event on Phase U. The overvoltage event is triggered when the measured phase voltage is over the programmed voltage limit.";
CM_ SG_ 2265415686 Phase_U_undervoltage_7 "Indicates an undervoltage event on Phase U. The overvoltage event is triggered when the measured phase voltage is over the programmed voltage limit.";
CM_ SG_ 2265415686 Phase_V_overvoltage_7 "Indicates an overvoltage event on Phase V. The overvoltage event is triggered when the measured phase voltage is over the programmed voltage limit.";
CM_ SG_ 2265415686 Phase_V_undervoltage_7 "Indicates an undervoltage event on Phase U. The overvoltage event is triggered when the measured phase voltage is over the programmed voltage limit.";
CM_ SG_ 2265415686 Phase_V_overcurrent_7 "Indicates an overcurrent event on Phase U. The overcurrent event is triggered when the measured phase current is over the programmed current limit.";
CM_ SG_ 2265415686 Phase_W_overvoltage_7 "Indicates an overvoltage event on Phase U. The overvoltage event is triggered when the measured phase voltage is over the programmed voltage limit.";
CM_ SG_ 2265415686 Phase_W_undervoltage_7 "Indicates an undervoltage event on Phase U. The overvoltage event is triggered when the measured phase voltage is over the programmed voltage limit.";
CM_ SG_ 2265415686 Phase_W_overcurrent_7 "Indicates an overcurrent event on Phase U. The overcurrent event is triggered when the measured phase current is over the programmed current limit.";
CM_ SG_ 2265415686 DC_undervoltage_7 "DC bus undervoltage condition. The undervoltage condition is asserted when the measured dc bus voltage is under the programmed voltage limit.";
CM_ SG_ 2265415686 DC_overvoltage_7 "DC bus overvoltage condition. The overvoltage condition is asserted when the measured dc bus voltage is over the programmed voltage limit.";
CM_ SG_ 2265415686 MOSFET_overtemperature_7 "This flag is asserted when the temperature of the MOSFET block is too high.";
CM_ SG_ 2265415686 Inductor_overtemperature_7 "This flag is asserted when the temperature of the inductor block is too high.";
CM_ SG_ 2265415686 Keep_Alive_not_served_7 "The Keep Alive feature is enabled but it was not served with the periodic message.";
CM_ SG_ 2265415686 PLL_not_locked_7 "Flag asserted when in rectifier modes, the PLL went out of lock condition";
CM_ SG_ 2265415686 Measurement_system_failure_7 "The voltages/currents measurement system is malfunctionning, and readouts are not guaranteed to be accurate.";
CM_ SG_ 2265415686 EEPROM_failure_7 "The configuration EEPROM failed to load or save the module configuration.";
CM_ SG_ 2265415683 Phase_U_7 "Phase current is the MOSFET loop current, in the branch U of the converter.";
CM_ SG_ 2265415683 Phase_V_7 "Phase current is the MOSFET loop current, in the branch V of the converter.";
CM_ SG_ 2265415683 Phase_W_7 "Phase current is the MOSFET loop current, in the branch W of the converter.";
CM_ SG_ 2265415696 Bus_current_7 "DC Bus current is possitive when current goes from input to output";
CM_ SG_ 2265415694 Phase_U_7 "Phase current is the MOSFET loop current, in the branch U of the converter.";
CM_ SG_ 2265415694 Phase_V_7 "Phase current is the MOSFET loop current, in the branch V of the converter.";
CM_ SG_ 2265415694 Phase_W_7 "Phase current is the MOSFET loop current, in the branch W of the converter.";
CM_ SG_ 2265415694 Stack_position_7 "Sender Stack position";
CM_ SG_ 2265415694 Group_ID_7 "Sender Group ID";
CM_ SG_ 2265415691 Phase_U_7 "RMS Phase current is the MOSFET loop current, in the branch U of the converter.";
CM_ SG_ 2265415691 Phase_V_7 "RMS Phase current is the MOSFET loop current, in the branch V of the converter.";
CM_ SG_ 2265415691 Phase_W_7 "RMS Phase current is the MOSFET loop current, in the branch W of the converter.";
CM_ SG_ 2265415692 Frequency_7 "Frequency of Three-Phase system";
CM_ SG_ 2265415692 Phase_7 "Phase of Three-Phase system";
CM_ SG_ 2265415685 Temp_Bridge_7 "Temperature of the MOSFET block";
CM_ SG_ 2265415685 Temp_Inductors_7 "Temperature of the inductors";
CM_ SG_ 2265415688 Phase_U_7 "The actual PWM duty cycle setpoint";
CM_ SG_ 2265415688 Phase_V_7 "The actual PWM duty cycle setpoint";
CM_ SG_ 2265415688 Phase_W_7 "The actual PWM duty cycle setpoint";
CM_ SG_ 2265415689 Current_setpoint_7 "The actual current setpoint";
CM_ SG_ 2265415689 Voltage_setpoint_7 "The actual voltage setpoint";
CM_ SG_ 2265415689 Frequency_setpoint_7 "The actual frequency setpoint";
CM_ SG_ 2265383008 Keep_Alive_Enable_7 "If set to 1, module will expect to receive this message every second repeatedly, or it will stop operation";
CM_ SG_ 2265382976 Converter_ON_7 "Enable the converter.";
CM_ SG_ 2265382976 PWM_ON_7 "Enable the PWM control mode.";
CM_ SG_ 2265382976 DC_Current_feedback_ON_7 "Enable the DC current loop";
CM_ SG_ 2265382976 AC_Current_feedback_ON_7 "Enable the AC current loop";
CM_ SG_ 2265382976 Buck_ON_7 "Enable the buck control mode.";
CM_ SG_ 2265382976 Boost_ON_7 "Enable the boost control mode.";
CM_ SG_ 2265382976 Rectifier_3ph_ON_7 "Enable the three-phase rectifier control mode.";
CM_ SG_ 2265382976 Inverter_1ph_ON_7 "Enable the single-phase inverter control mode.";
CM_ SG_ 2265382976 Rectifier_1ph_ON_7 "Enable the single-phase rectifier control mode.";
CM_ SG_ 2265382976 Boost_Neutral_ON_7 "Enable the boost control mode with neutral generation.";
CM_ SG_ 2265382976 Inverter_3ph_ON_7 "Enable the three-phase inverter control mode.";
CM_ SG_ 2265382976 Inverter_1ph_Sync_ON_7 "Single-phase inverter control mode with phase synchronization.";
CM_ SG_ 2265382976 Neutral_ON_7 "Open-loop neutral generation.";
CM_ SG_ 2265382976 Rectifier_1ph_Buck_ON_7 "Single-phase rectifier with buck on one leg.";
CM_ SG_ 2265382976 Inverter_1ph_Boost_ON_7 "Single-phase inverter with boost on one leg.";
CM_ SG_ 2265382976 Rectifier_Distributed_ON_7 "Single-phase (floating) distributed rectifier";
CM_ SG_ 2265382976 MPPT_buck_ON_7 "MPPT buck";
CM_ SG_ 2265382976 MPPT_boost_ON_7 "MPPT boost";
CM_ SG_ 2265382976 Buck_2p_float_ON_7 "Boost on L1 and L2. Floating L3 (high-impedance)";
CM_ SG_ 2265382976 Inverter_1ph_Distributed_ON_7 "Single-phase inverter mode distributed";
CM_ SG_ 2265382992 Clear_Interlock_7 "Clears the converter interlock";
CM_ SG_ 2265382992 Reset_Processor_7 "Reset the converter DSP";
CM_ SG_ 2265382992 Trip_Interlock_7 "Trip the inetrnal Interlock";
CM_ SG_ 2265382977 Reactive_current_setpoint_7 "This defines reactive current setpoint for 3-phase rectifier mode";
CM_ SG_ 2265382978 Phase_U_7 "The actual PWM duty cycle setpoint";
CM_ SG_ 2265382978 Phase_V_7 "The actual PWM duty cycle setpoint";
CM_ SG_ 2265382978 Phase_W_7 "The actual PWM duty cycle setpoint";
CM_ SG_ 2265382979 Current_setpoint_7 "Sets the output current setpoint. Active only when the current loop is enabled";
CM_ SG_ 2265382980 Voltage_setpoint_7 "Sets the output voltage setpoint. Active only when the voltage loop is enabled";
CM_ SG_ 2265382984 Frequency_setpoint_7 "Sets the frequency for single-phase and three-phase generator modes.";
CM_ SG_ 2265382985 Phase_setpoint_7 "Sets the phase for inverter control modes.";
CM_ SG_ 2265382981 Stack_position_7 "The converter position within the stack";
CM_ SG_ 2265382981 Stack_size_7 "How many PFC converters are in stack in total";
CM_ SG_ 2265382981 SN_number_7 "Unique module serial number";
CM_ SG_ 2265382960 Phase_voltage_min_7 "Minimum tolerated phase voltage";
CM_ SG_ 2265382960 Phase_voltage_max_7 "Maximum allowable phase voltage";
CM_ SG_ 2265382960 DC_voltage_min_7 "Minimum allowable dc voltage";
CM_ SG_ 2265382960 DC_voltage_max_7 "Maximum allowable dc voltage";
CM_ SG_ 2265382961 Phase_current_min_7 "Minimum allowable output current";
CM_ SG_ 2265382961 Phase_current_max_7 "Maximum allowable output current";
CM_ SG_ 2265382988 Group_ID_7 "Desired group ID for the device";
CM_ SG_ 2265415695 Group_ID_7 "Group ID of the device";
CM_ SG_ 2265383009 Factory_mode_7 "Customers MUST NOT USE this bit. If set to 1, module will enter in factory mode. ";
CM_ SG_ 2265383009 Silent_CAN_mode_7 "Customers MUST NOT USE this bit. If set to 1, module will enter in factory mode. ";
CM_ SG_ 2265382986 start_7 "Start automatic calibration. Multiplexer index must be 0!";
CM_ SG_ 2265382987 point_7 "Calibration point index.";
CM_ SG_ 2265382982 CRC_7 "Checksum of bytes 0 to 3, CRC-CCITT, corresponding to qChecksum (www.qt.io)";
CM_ SG_ 2265382983 CRC_7 "Checksum of bytes 0 to 3, CRC-CCITT, corresponding to qChecksum (www.qt.io)";
CM_ SG_ 2265415766 Current_U_High_7 "This flag is set if a hight current on U tripped the internal interlock";
CM_ SG_ 2265415766 Current_U_Low_7 "This flag is set if a low current on U tripped the internal interlock";
CM_ SG_ 2265415766 Current_V_High_7 "This flag is set if a hight current on V tripped the internal interlock";
CM_ SG_ 2265415766 Current_V_Low_7 "This flag is set if a low current on V tripped the internal interlock";
CM_ SG_ 2265415766 Current_W_High_7 "This flag is set if a hight current on W tripped the internal interlock";
CM_ SG_ 2265415766 Current_W_Low_7 "This flag is set if a low current on W tripped the internal interlock";
CM_ SG_ 2265415766 Voltage_DC_7 "This flag is set if a voltage on DC tripped the internal interlock";
CM_ SG_ 2265415766 Reboot_7 "This flag is set if a reboot tripped the internal interlock";
CM_ SG_ 2265415766 Unknown_7 "This flag the reason for the internal interlock is unknown";

BA_DEF_ BO_ "SystemMessageLongSymbol" STRING;

BA_ "SystemMessageLongSymbol" BO_ 2265382977 "AFE_Reactive_Current_Setpoint_Control_7";

VAL_ 2265415680 Device_type_7 7 "AFE";
VAL_ 2265415686 Protection_trip_internal_7 1 "fault";
VAL_ 2265415686 Protection_trip_external_7 1 "fault";
VAL_ 2265415686 Phase_U_overcurrent_7 1 "fault";
VAL_ 2265415686 Phase_U_overvoltage_7 1 "fault";
VAL_ 2265415686 Phase_U_undervoltage_7 1 "fault";
VAL_ 2265415686 Phase_V_overvoltage_7 1 "fault";
VAL_ 2265415686 Phase_V_undervoltage_7 1 "fault";
VAL_ 2265415686 Phase_V_overcurrent_7 1 "fault";
VAL_ 2265415686 Phase_W_overvoltage_7 1 "fault";
VAL_ 2265415686 Phase_W_undervoltage_7 1 "fault";
VAL_ 2265415686 Phase_W_overcurrent_7 1 "fault";
VAL_ 2265415686 DC_undervoltage_7 1 "fault";
VAL_ 2265415686 DC_overvoltage_7 1 "fault";
VAL_ 2265415686 MOSFET_overtemperature_7 1 "fault";
VAL_ 2265415686 Inductor_overtemperature_7 1 "fault";
VAL_ 2265415686 Keep_Alive_not_served_7 1 "fault";
VAL_ 2265415686 PLL_not_locked_7 1 "fault";
VAL_ 2265415686 NFO_7 1 "fault";
VAL_ 2265415686 Measurement_system_failure_7 1 "fault";
VAL_ 2265415686 EEPROM_failure_7 1 "fault";
VAL_ 2265415686 System_7 1 "fault";
VAL_ 2265415766 Current_U_High_7 1 "fault";
VAL_ 2265415766 Current_U_Low_7 1 "fault";
VAL_ 2265415766 Current_V_High_7 1 "fault";
VAL_ 2265415766 Current_V_Low_7 1 "fault";
VAL_ 2265415766 Current_W_High_7 1 "fault";
VAL_ 2265415766 Current_W_Low_7 1 "fault";
VAL_ 2265415766 Voltage_DC_7 1 "fault";
VAL_ 2265415766 Reboot_7 1 "fault";
VAL_ 2265415766 Unknown_7 1 "fault";
SIG_VALTYPE_ 2265415761 Current_U_7 : 1;
SIG_VALTYPE_ 2265415761 Current_V_7 : 1;
SIG_VALTYPE_ 2265415761 Current_W_7 : 1;
SIG_VALTYPE_ 2265415761 Voltage_U_7 : 1;
SIG_VALTYPE_ 2265415761 Voltage_V_7 : 1;
SIG_VALTYPE_ 2265415761 Voltage_W_7 : 1;
SIG_VALTYPE_ 2265415761 Voltage_DC_7 : 1;
SIG_VALTYPE_ 2265415762 Current_U_7 : 1;
SIG_VALTYPE_ 2265415762 Current_V_7 : 1;
SIG_VALTYPE_ 2265415762 Current_W_7 : 1;
SIG_VALTYPE_ 2265415762 Voltage_U_7 : 1;
SIG_VALTYPE_ 2265415762 Voltage_V_7 : 1;
SIG_VALTYPE_ 2265415762 Voltage_W_7 : 1;
SIG_VALTYPE_ 2265415762 Voltage_DC_7 : 1;
